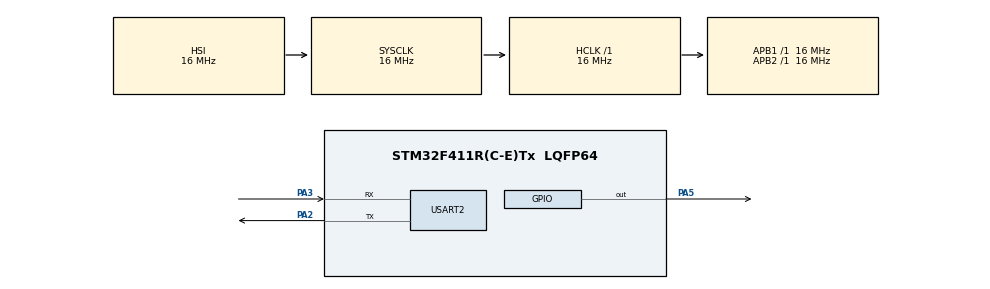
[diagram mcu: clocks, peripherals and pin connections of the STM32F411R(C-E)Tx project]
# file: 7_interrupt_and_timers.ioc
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FREERTOS.Tasks01=defaultTask,24,128,StartDefaultTask,Default,NULL,Dynamic,NULL,NULL
FREERTOS.configUSE_NEWLIB_REENTRANT=1
Mcu.Family=STM32F4
Mcu.Name=STM32F411R(C-E)Tx
Mcu.Package=LQFP64
NVIC.PriorityGroup=NVIC_PRIORITYGROUP_4
NVIC.TIM1_TRG_COM_TIM11_IRQn=true\:15\:0\:false\:false\:true\:false\:false\:true\:true
NVIC.TIM3_IRQn=true\:5\:0\:false\:false\:true\:true\:true\:true\:true
NVIC.TimeBase=TIM1_TRG_COM_TIM11_IRQn
NVIC.TimeBaseIP=TIM11
PA2.Mode=Asynchronous
PA2.Signal=USART2_TX
PA3.Mode=Asynchronous
PA3.Signal=USART2_RX
PA5.Signal=GPIO_Output
PH0\ -\ OSC_IN.Mode=HSE-External-Oscillator
PH0\ -\ OSC_IN.Signal=RCC_OSC_IN
PH1\ -\ OSC_OUT.Mode=HSE-External-Oscillator
PH1\ -\ OSC_OUT.Signal=RCC_OSC_OUT
ProjectManager.HeapSize=0x200
ProjectManager.StackSize=0x400
ProjectManager.TargetToolchain=STM32CubeIDE
RCC.AHBFreq_Value=16000000
RCC.APB1Freq_Value=16000000
RCC.APB2Freq_Value=16000000
RCC.CortexFreq_Value=16000000
RCC.HSE_VALUE=25000000
RCC.HSI_VALUE=16000000
RCC.LSE_VALUE=32768
RCC.SYSCLKFreq_VALUE=16000000
RCC.VCOOutputFreq_Value=192000000
TIM3.Period=9999
TIM3.Prescaler=1599
USART2.VirtualMode=VM_ASYNC
VP_FREERTOS_VS_CMSIS_V2.Mode=CMSIS_V2
VP_SYS_VS_tim11.Mode=TIM11
VP_TIM3_VS_ClockSourceINT.Mode=Internal
board=custom

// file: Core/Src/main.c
/* USER CODE BEGIN Header */
/**
 ******************************************************************************
 * @file           : main.c
 * @brief          : Main program body
 ******************************************************************************
 * @attention
 *
 * Copyright (c) 2026 STMicroelectronics.
 * All rights reserved.
 *
 * This software is licensed under terms that can be found in the LICENSE file
 * in the root directory of this software component.
 * If no LICENSE file comes with this software, it is provided AS-IS.
 *
 ******************************************************************************
 */
/* USER CODE END Header */
#include "main.h"
#include "cmsis_os.h"

/* USER CODE BEGIN Includes */

/* Standard library includes */
#include <stdio.h>
#include <stdlib.h>
#include <string.h>
#include <math.h>

/* FreeRTOS includes */
#include "timers.h"
#include "semphr.h"

/* User includes */

/* USER CODE END Includes */

TIM_HandleTypeDef htim3;

UART_HandleTypeDef huart2;

/* Definitions for defaultTask */
osThreadId_t defaultTaskHandle;
const osThreadAttr_t defaultTask_attributes = { .name = "defaultTask",
		.stack_size = 128 * 4, .priority = (osPriority_t) osPriorityNormal, };
/* USER CODE BEGIN PV */

/* ----------------------------- VARIABLES ---------------------------- */

static const TickType_t task_delay = 2000 / portTICK_PERIOD_MS;
static volatile int isr_counter;

/* ----------------------------- CALLBACKS ---------------------------- */

/* ------------------------------ TASKS ------------------------------ */

osThreadId_t printTaskHandle;
const osThreadAttr_t printTask_attributes = { .name = "printTask",
		.stack_size = 512 * 4, .priority = (osPriority_t) osPriorityNormal, };

/* USER CODE END PV */

void SystemClock_Config(void);
static void MX_GPIO_Init(void);
static void MX_USART2_UART_Init(void);
static void MX_TIM3_Init(void);
void StartDefaultTask(void *argument);

/* USER CODE BEGIN PFP */

/* ------------------------ FUNCTION SIGNATURES ----------------------- */

/* USER CODE END PFP */

int main(void) {

	/* MCU Configuration--------------------------------------------------------*/

	/* Reset of all peripherals, Initializes the Flash interface and the Systick. */
	HAL_Init();

	/* Configure the system clock */
	SystemClock_Config();

	/* Initialize all configured peripherals */
	MX_GPIO_Init();
	MX_USART2_UART_Init();
	MX_TIM3_Init();
	/* USER CODE BEGIN 2 */

	/* Disable internal buffering for stdin */
	setvbuf(stdin, NULL, _IONBF, 0);

	/* USER CODE END 2 */

	/* Init scheduler */
	osKernelInitialize();

	/* Create the thread(s) */
	/* creation of defaultTask */
	defaultTaskHandle = osThreadNew(StartDefaultTask, NULL,
			&defaultTask_attributes);

	/* Start scheduler */
	osKernelStart();

	/* We should never get here as control is now taken by the scheduler */

	/* Infinite loop */
	while (1) {

	}
}

void SystemClock_Config(void) {
	RCC_OscInitTypeDef RCC_OscInitStruct = { 0 };
	RCC_ClkInitTypeDef RCC_ClkInitStruct = { 0 };

	/** Configure the main internal regulator output voltage
	 */
	__HAL_RCC_PWR_CLK_ENABLE();
	__HAL_PWR_VOLTAGESCALING_CONFIG(PWR_REGULATOR_VOLTAGE_SCALE1);

	/** Initializes the RCC Oscillators according to the specified parameters
	 * in the RCC_OscInitTypeDef structure.
	 */
	RCC_OscInitStruct.OscillatorType = RCC_OSCILLATORTYPE_HSI;
	RCC_OscInitStruct.HSIState = RCC_HSI_ON;
	RCC_OscInitStruct.HSICalibrationValue = RCC_HSICALIBRATION_DEFAULT;
	RCC_OscInitStruct.PLL.PLLState = RCC_PLL_NONE;
	if (HAL_RCC_OscConfig(&RCC_OscInitStruct) != HAL_OK) {
		Error_Handler();
	}

	/** Initializes the CPU, AHB and APB buses clocks
	 */
	RCC_ClkInitStruct.ClockType = RCC_CLOCKTYPE_HCLK | RCC_CLOCKTYPE_SYSCLK
			| RCC_CLOCKTYPE_PCLK1 | RCC_CLOCKTYPE_PCLK2;
	RCC_ClkInitStruct.SYSCLKSource = RCC_SYSCLKSOURCE_HSI;
	RCC_ClkInitStruct.AHBCLKDivider = RCC_SYSCLK_DIV1;
	RCC_ClkInitStruct.APB1CLKDivider = RCC_HCLK_DIV1;
	RCC_ClkInitStruct.APB2CLKDivider = RCC_HCLK_DIV1;

	if (HAL_RCC_ClockConfig(&RCC_ClkInitStruct, FLASH_LATENCY_0) != HAL_OK) {
		Error_Handler();
	}
}

static void MX_TIM3_Init(void) {

	TIM_ClockConfigTypeDef sClockSourceConfig = { 0 };
	TIM_MasterConfigTypeDef sMasterConfig = { 0 };

	htim3.Instance = TIM3;
	htim3.Init.Prescaler = 1599;
	htim3.Init.CounterMode = TIM_COUNTERMODE_UP;
	htim3.Init.Period = 999;
	htim3.Init.ClockDivision = TIM_CLOCKDIVISION_DIV1;
	htim3.Init.AutoReloadPreload = TIM_AUTORELOAD_PRELOAD_DISABLE;
	if (HAL_TIM_Base_Init(&htim3) != HAL_OK) {
		Error_Handler();
	}
	sClockSourceConfig.ClockSource = TIM_CLOCKSOURCE_INTERNAL;
	if (HAL_TIM_ConfigClockSource(&htim3, &sClockSourceConfig) != HAL_OK) {
		Error_Handler();
	}
	sMasterConfig.MasterOutputTrigger = TIM_TRGO_RESET;
	sMasterConfig.MasterSlaveMode = TIM_MASTERSLAVEMODE_DISABLE;
	if (HAL_TIMEx_MasterConfigSynchronization(&htim3, &sMasterConfig)
			!= HAL_OK) {
		Error_Handler();
	}
	/* USER CODE BEGIN TIM3_Init 2 */
	HAL_TIM_Base_Start_IT(&htim3);
	/* USER CODE END TIM3_Init 2 */

}

static void MX_USART2_UART_Init(void) {

	huart2.Instance = USART2;
	huart2.Init.BaudRate = 115200;
	huart2.Init.WordLength = UART_WORDLENGTH_8B;
	huart2.Init.StopBits = UART_STOPBITS_1;
	huart2.Init.Parity = UART_PARITY_NONE;
	huart2.Init.Mode = UART_MODE_TX_RX;
	huart2.Init.HwFlowCtl = UART_HWCONTROL_NONE;
	huart2.Init.OverSampling = UART_OVERSAMPLING_16;
	if (HAL_UART_Init(&huart2) != HAL_OK) {
		Error_Handler();
	}

}

static void MX_GPIO_Init(void) {
	GPIO_InitTypeDef GPIO_InitStruct = { 0 };

	/* GPIO Ports Clock Enable */
	__HAL_RCC_GPIOH_CLK_ENABLE();
	__HAL_RCC_GPIOA_CLK_ENABLE();

	/*Configure GPIO pin Output Level */
	HAL_GPIO_WritePin(GPIOA, GPIO_PIN_5, GPIO_PIN_RESET);

	/*Configure GPIO pin : PA5 */
	GPIO_InitStruct.Pin = GPIO_PIN_5;
	GPIO_InitStruct.Mode = GPIO_MODE_OUTPUT_PP;
	GPIO_InitStruct.Pull = GPIO_NOPULL;
	GPIO_InitStruct.Speed = GPIO_SPEED_FREQ_LOW;
	HAL_GPIO_Init(GPIOA, &GPIO_InitStruct);

}

/* USER CODE BEGIN 4 */

/* ----------------------- FUNCTION DEFINITIONS ----------------------- */

/* printf redirection */
int __io_putchar(int ch) {
	HAL_UART_Transmit(&huart2, (uint8_t*) &ch, 1, HAL_MAX_DELAY);
	return ch;
}

/* scanf redirection */
int __io_getchar(void) {
	uint8_t ch = 0;

	/* Clear the Overrun flag before reading the first character */
	/* Only clear overrun flag if overrun actually occurred */
	if (__HAL_UART_GET_FLAG(&huart2, UART_FLAG_ORE)) {
		__HAL_UART_CLEAR_OREFLAG(&huart2);
	}

	HAL_UART_Receive(&huart2, (uint8_t*) &ch, 1, HAL_MAX_DELAY);

	if (ch == '\r')
		ch = '\n';  // Convert CR to LF so gets() terminates

	HAL_UART_Transmit(&huart2, (uint8_t*) &ch, 1, HAL_MAX_DELAY);
	return ch;
}

/* ------------------- FUNCTION DEFINITIONS (TASKS) ------------------- */

void StartPrintTask(void *argument) {
	for(;;) {
		while (isr_counter > 0) {
			printf("%d\r\n", isr_counter);

			/* This is NOT a mutex, as this prevents interrupts */

			/* This is not done inside an ISR */
			taskENTER_CRITICAL();
			isr_counter--;
			taskEXIT_CRITICAL();
		}

		/* Wait while ISR increments counter for a few times */
		vTaskDelay(task_delay);
	}
}

/* USER CODE END 4 */

void StartDefaultTask(void *argument) {
	/* USER CODE BEGIN 5 */
	printTaskHandle = osThreadNew(StartPrintTask, NULL, &printTask_attributes);
	vTaskDelete(NULL);
	/* USER CODE END 5 */
}

void HAL_TIM_PeriodElapsedCallback(TIM_HandleTypeDef *htim) {
	/* USER CODE BEGIN Callback 0 */
	if (htim->Instance == TIM3) {
		/* This is NOT a mutex, as this prevents interrupts */
		/* Note that the functions for entering and exiting */
		/* the critical regions are different, as its from inside an ISR*/
		UBaseType_t uxSavedInterruptStatus = taskENTER_CRITICAL_FROM_ISR();
		isr_counter++;
		taskEXIT_CRITICAL_FROM_ISR(uxSavedInterruptStatus);
	}

	/* USER CODE END Callback 0 */
	if (htim->Instance == TIM11) {
		HAL_IncTick();
	}
}

void Error_Handler(void) {
	__disable_irq();
	while (1) {
	}
}
